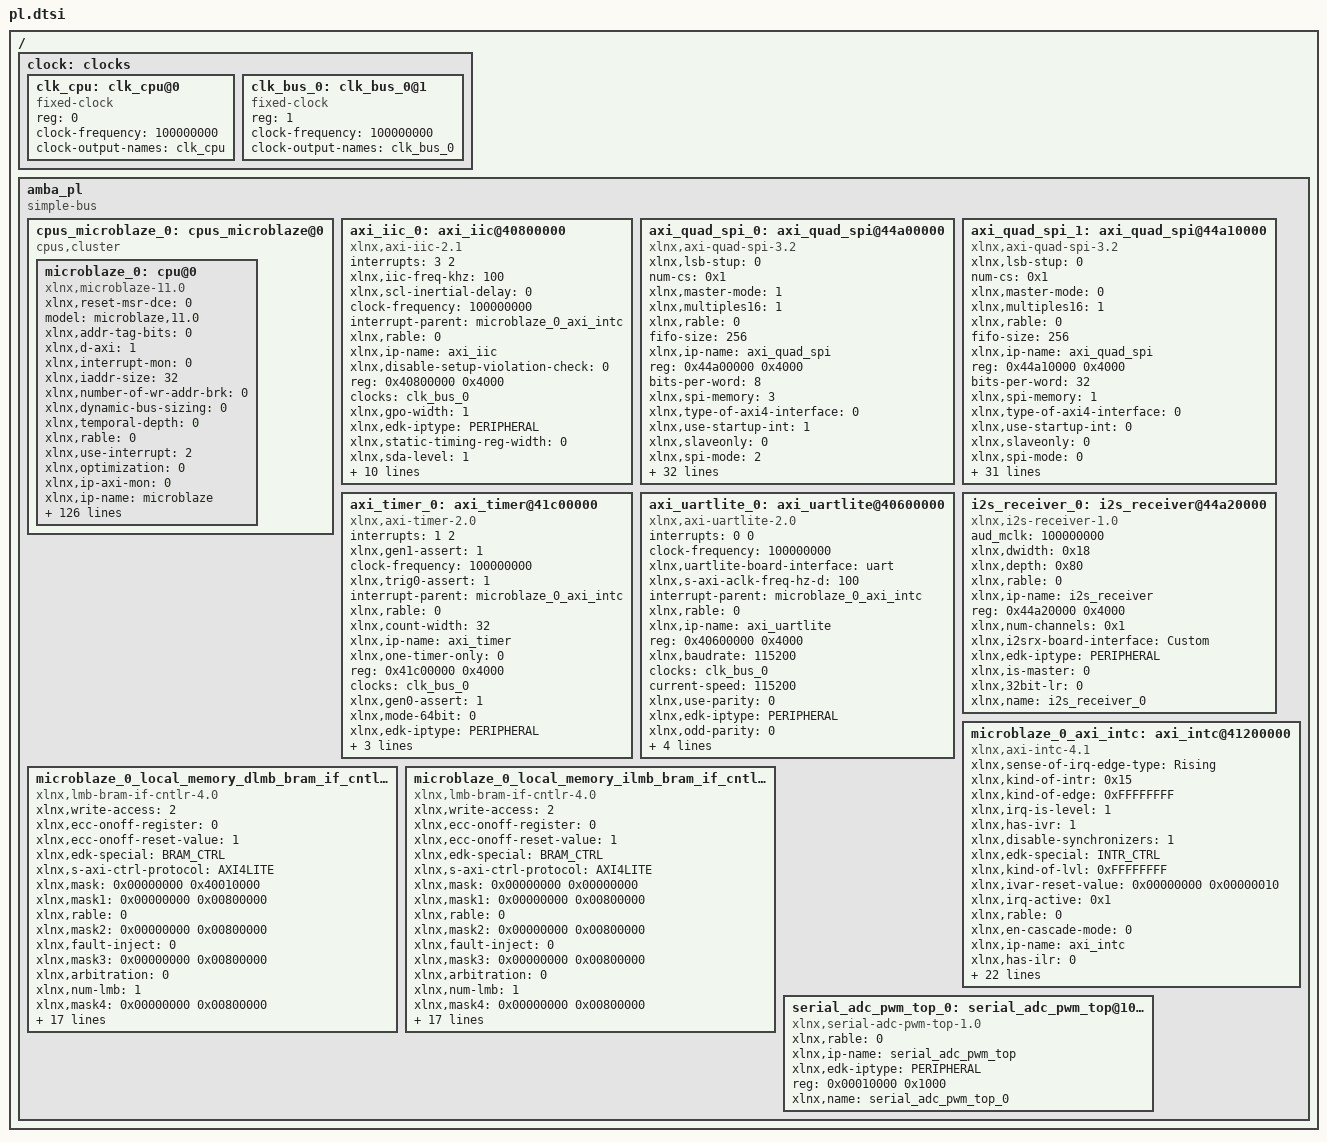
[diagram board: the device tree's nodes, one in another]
/ {
	clock: clocks {
		#address-cells = <1>;
		#size-cells = <0>;
		clk_cpu: clk_cpu@0 {
			compatible = "fixed-clock";
			reg = <0>;
			clock-frequency = <100000000>;
			clock-output-names = "clk_cpu";
			#clock-cells = <0>;
		};
		clk_bus_0: clk_bus_0@1 {
			compatible = "fixed-clock";
			reg = <1>;
			clock-frequency = <100000000>;
			clock-output-names = "clk_bus_0";
			#clock-cells = <0>;
		};
	};
	amba_pl: amba_pl {
		ranges;
		compatible = "simple-bus";
		#address-cells = <1>;
		#size-cells = <1>;
		cpus_microblaze_0: cpus_microblaze@0 {
			#cpu-mask-cells = <1>;
			compatible = "cpus,cluster";
			microblaze_0: cpu@0 {
				xlnx,reset-msr-dce = <0>;
				model = "microblaze,11.0";
				xlnx,addr-tag-bits = <0>;
				xlnx,d-axi = <1>;
				xlnx,interrupt-mon = <0>;
				xlnx,iaddr-size = <32>;
				xlnx,number-of-wr-addr-brk = <0>;
				xlnx,dynamic-bus-sizing = <0>;
				xlnx,temporal-depth = <0>;
				xlnx,rable = <0>;
				xlnx,use-interrupt = <2>;
				xlnx,optimization = <0>;
				xlnx,ip-axi-mon = <0>;
				xlnx,ip-name = "microblaze";
				d-cache-highaddr = <0x3fffffff>;
				xlnx,dcache-force-tag-lutram = <0>;
				xlnx,pc-width = <32>;
				xlnx,interrupt-is-edge = <0>;
				reg = <0x0>;
				xlnx,async-interrupt = <1>;
				xlnx,use-mmu = <0>;
				xlnx,reset-msr-ee = <0>;
				xlnx,icache-victims = <0>;
				xlnx,use-reorder-instr = <0>;
				xlnx,d-lmb-mon = <0>;
				xlnx,d-lmb-protocol = <0>;
				xlnx,ill-opcode-exception = <0>;
				xlnx,dcache-always-used = <1>;
				xlnx,use-div = <0>;
				xlnx,dc-axi-mon = <0>;
				xlnx,debug-trace-async-reset = <0>;
				xlnx,trace = <0>;
				xlnx,part = "xc7a100tcsg324-2";
				i-cache-baseaddr = <0x00000000>;
				xlnx,use-config-reset = <0>;
				xlnx,pvr = <0>;
				xlnx,i-lmb-mon = <0>;
				xlnx,dcache-byte-size = <4096>;
				xlnx,fault-tolerant = <0>;
				xlnx,family = "artix7";
				compatible = "xlnx,microblaze-11.0" , "xlnx,microblaze";
				xlnx,data-size = <32>;
				xlnx,mmu-zones = <2>;
				xlnx,debug-trace-size = <8192>;
				xlnx,mmu-privileged-instr = <0>;
				xlnx,enable-discrete-ports = <0>;
				d-cache-line-size = <16>;
				xlnx,d-lmb = <1>;
				xlnx,sco = <0>;
				xlnx,reset-msr-eip = <0>;
				clock-frequency = <100000000>;
				xlnx,debug-interface = <0>;
				xlnx,use-ext-brk = <0>;
				xlnx,daddr-size = <32>;
				xlnx,debug-enabled = <1>;
				xlnx,reset-msr-ice = <0>;
				xlnx,num-sync-ff-dbg-trace-clk = <2>;
				xlnx,i-lmb-protocol = <0>;
				xlnx,endianness = <1>;
				xlnx,fsl-exception = <0>;
				i-cache-line-size = <16>;
				xlnx,use-extended-fsl-instr = <0>;
				xlnx,reset-msr = <0x00000000>;
				xlnx,dp-axi-mon = <0>;
				xlnx,branch-target-cache-size = <0>;
				xlnx,dcache-use-writeback = <0>;
				xlnx,div-zero-exception = <0>;
				xlnx,mmu-tlb-access = <3>;
				bus-handle = <&amba_pl>;
				xlnx,cache-byte-size = <4096>;
				xlnx,pvr-user2 = <0x00000000>;
				xlnx,opcode-0x0-illegal = <0>;
				xlnx,icache-line-len = <4>;
				xlnx,ecc-use-ce-exception = <0>;
				xlnx,base-vectors = <0x00000000 0x00000000>;
				xlnx,use-dcache = <0>;
				xlnx,use-barrel = <1>;
				xlnx,reset-msr-bip = <0>;
				xlnx,edk-special = "microblaze";
				xlnx,allow-dcache-wr = <1>;
				xlnx,addr-size = <32>;
				xlnx,debug-external-trace = <0>;
				xlnx,piaddr-size = <32>;
				i-cache-highaddr = <0x3fffffff>;
				xlnx,num-sync-ff-clk-debug = <2>;
				xlnx,debug-event-counters = <5>;
				xlnx,fpu-exception = <0>;
				xlnx,allow-icache-wr = <1>;
				xlnx,i-axi = <0>;
				xlnx,g-use-exceptions = <0>;
				xlnx,icache-streams = <0>;
				xlnx,g-template-list = <8>;
				xlnx,dcache-line-len = <4>;
				xlnx,num-sync-ff-clk = <2>;
				xlnx,use-stack-protection = <0>;
				xlnx,use-hw-mul = <1>;
				xlnx,num-sync-ff-dbg-clk = <1>;
				xlnx,interconnect = <2>;
				xlnx,edk-iptype = "PROCESSOR";
				xlnx,debug-latency-counters = <1>;
				i-cache-size = <4096>;
				xlnx,use-fpu = <0>;
				xlnx,reset-msr-ie = <0>;
				xlnx,edge-is-positive = <1>;
				xlnx,use-pcmp-instr = <1>;
				xlnx,use-icache = <0>;
				d-cache-size = <4096>;
				xlnx,async-wakeup = <3>;
				xlnx,use-non-secure = <0>;
				xlnx,dcache-addr-tag = <0>;
				xlnx,number-of-rd-addr-brk = <0>;
				d-cache-baseaddr = <0x00000000>;
				xlnx,area-optimized = <1>;
				xlnx,avoid-primitives = <0>;
				xlnx,lockstep-slave = <0>;
				xlnx,use-ext-nm-brk = <0>;
				xlnx,instr-size = <32>;
				interrupt-handle = <&microblaze_0_axi_intc>;
				xlnx,icache-always-used = <1>;
				xlnx,i-lmb = <1>;
				xlnx,mmu-dtlb-size = <2>;
				xlnx,lockstep-select = <0>;
				xlnx,lmb-data-size = <32>;
				xlnx,ic-axi-mon = <0>;
				xlnx,num-sync-ff-clk-irq = <1>;
				xlnx,fsl-links = <0>;
				timebase-frequency = <100000000>;
				xlnx,icache-force-tag-lutram = <0>;
				xlnx,dcache-data-width = <0>;
				xlnx,dcache-victims = <0>;
				xlnx,use-branch-target-cache = <0>;
				xlnx,debug-profile-size = <0>;
				xlnx,unaligned-exceptions = <0>;
				xlnx,lockstep-master = <0>;
				xlnx,freq = <100000000>;
				xlnx,number-of-pc-brk = <1>;
				xlnx,mmu-itlb-size = <1>;
				xlnx,imprecise-exceptions = <0>;
				xlnx,use-msr-instr = <1>;
				xlnx,icache-data-width = <0>;
				xlnx,debug-counter-width = <32>;
			};
		};
		axi_iic_0: axi_iic@40800000 {
			interrupts = < 3 2 >;
			xlnx,iic-freq-khz = <100>;
			compatible = "xlnx,axi-iic-2.1" , "xlnx,xps-iic-2.00.a";
			xlnx,scl-inertial-delay = <0>;
			clock-frequency = <100000000>;
			interrupt-parent = <&microblaze_0_axi_intc>;
			xlnx,rable = <0>;
			xlnx,ip-name = "axi_iic";
			xlnx,disable-setup-violation-check = <0>;
			reg = <0x40800000 0x4000>;
			clocks = <&clk_bus_0>;
			xlnx,gpo-width = <1>;
			xlnx,edk-iptype = "PERIPHERAL";
			xlnx,static-timing-reg-width = <0>;
			xlnx,sda-level = <1>;
			status = "okay";
			xlnx,use-board-flow;
			xlnx,ten-bit-adr = <0>;
			xlnx,default-value = <0x00>;
			interrupt-names = "iic2intc_irpt";
			xlnx,timing-reg-width = <32>;
			xlnx,iic-board-interface = "iic_main";
			xlnx,iic-freq = <100000>;
			xlnx,smbus-pmbus-host = <0>;
			xlnx,sda-inertial-delay = <0>;
			xlnx,name = "axi_iic_0";
			xlnx,axi-aclk-freq-mhz = <100>;
		};
		axi_quad_spi_0: axi_quad_spi@44a00000 {
			xlnx,lsb-stup = <0>;
			num-cs = <0x1>;
			xlnx,master-mode = <1>;
			xlnx,multiples16 = <1>;
			xlnx,rable = <0>;
			fifo-size = <256>;
			xlnx,ip-name = "axi_quad_spi";
			reg = <0x44a00000 0x4000>;
			bits-per-word = <8>;
			xlnx,spi-memory = <3>;
			xlnx,type-of-axi4-interface = <0>;
			xlnx,use-startup-int = <1>;
			xlnx,slaveonly = <0>;
			xlnx,spi-mode = <2>;
			interrupt-names = "ip2intc_irpt";
			compatible = "xlnx,axi-quad-spi-3.2" , "xlnx,xps-spi-2.00.a";
			xlnx,byte-level-interrupt-en = <0>;
			xlnx,s-axi4-addr-width = <24>;
			xlnx,sck-ratio = <2>;
			interrupt-parent = <&microblaze_0_axi_intc>;
			xlnx,startup-block;
			xlnx,async-clk = <0>;
			status = "okay";
			xlnx,sck-ratio1 = <1>;
			xlnx,use-board-flow;
			xlnx,fifo-included = <1>;
			xlnx,name = "axi_quad_spi_0";
			interrupts = < 2 0 >;
			xlnx,use-startup-ext = <0>;
			xlnx,hasfifos = <1>;
			xlnx,s-axi4-id-width = <4>;
			xlnx,shared-startup = <0>;
			xlnx,new-seq-en = <1>;
			xlnx,qspi-board-interface = "spi_flash";
			xlnx,edk-iptype = "PERIPHERAL";
			xlnx,fifo-depth = <256>;
			xlnx,axi-interface = <0>;
			xlnx,num-ss-bits = <0x1>;
			xlnx,select-xpm = <0>;
			xlnx,xip-mode = <0>;
			xlnx,xip-perf-mode = <1>;
			xlnx,dual-quad-mode = <0>;
			xlnx,num-transfer-bits = <8>;
			xlnx,s-axi4-data-width = <32>;
			xlnx,use-startup = <1>;
			xlnx,spi-mem-addr-bits = <24>;
			xlnx,uc-family = <0>;
			xlnx,Axi4-address = <0>;
			xlnx,sub-family = "artix7";
		};
		axi_quad_spi_1: axi_quad_spi@44a10000 {
			xlnx,lsb-stup = <0>;
			num-cs = <0x1>;
			xlnx,master-mode = <0>;
			xlnx,multiples16 = <1>;
			xlnx,rable = <0>;
			fifo-size = <256>;
			xlnx,ip-name = "axi_quad_spi";
			reg = <0x44a10000 0x4000>;
			bits-per-word = <32>;
			xlnx,spi-memory = <1>;
			xlnx,type-of-axi4-interface = <0>;
			xlnx,use-startup-int = <0>;
			xlnx,slaveonly = <0>;
			xlnx,spi-mode = <0>;
			interrupt-names = "ip2intc_irpt";
			compatible = "xlnx,axi-quad-spi-3.2" , "xlnx,xps-spi-2.00.a";
			xlnx,byte-level-interrupt-en = <0>;
			xlnx,s-axi4-addr-width = <24>;
			xlnx,sck-ratio = <8>;
			interrupt-parent = <&microblaze_0_axi_intc>;
			xlnx,async-clk = <0>;
			status = "okay";
			xlnx,sck-ratio1 = <1>;
			xlnx,use-board-flow;
			xlnx,fifo-included = <1>;
			xlnx,name = "axi_quad_spi_1";
			interrupts = < 4 0 >;
			xlnx,use-startup-ext = <0>;
			xlnx,hasfifos = <1>;
			xlnx,s-axi4-id-width = <4>;
			xlnx,shared-startup = <0>;
			xlnx,new-seq-en = <1>;
			xlnx,qspi-board-interface = "Custom";
			xlnx,edk-iptype = "PERIPHERAL";
			xlnx,fifo-depth = <256>;
			xlnx,axi-interface = <0>;
			xlnx,num-ss-bits = <0x1>;
			xlnx,select-xpm = <0>;
			xlnx,xip-mode = <0>;
			xlnx,xip-perf-mode = <1>;
			xlnx,dual-quad-mode = <0>;
			xlnx,num-transfer-bits = <32>;
			xlnx,s-axi4-data-width = <32>;
			xlnx,use-startup = <0>;
			xlnx,spi-mem-addr-bits = <24>;
			xlnx,uc-family = <0>;
			xlnx,sub-family = "artix7";
			xlnx,Axi4-address = <0>;
		};
		axi_timer_0: axi_timer@41c00000 {
			interrupts = < 1 2 >;
			compatible = "xlnx,axi-timer-2.0" , "xlnx,xps-timer-1.00.a";
			xlnx,gen1-assert = <1>;
			clock-frequency = <100000000>;
			xlnx,trig0-assert = <1>;
			interrupt-parent = <&microblaze_0_axi_intc>;
			xlnx,rable = <0>;
			xlnx,count-width = <32>;
			xlnx,ip-name = "axi_timer";
			xlnx,one-timer-only = <0>;
			reg = <0x41c00000 0x4000>;
			clocks = <&clk_bus_0>;
			xlnx,gen0-assert = <1>;
			xlnx,mode-64bit = <0>;
			xlnx,edk-iptype = "PERIPHERAL";
			xlnx,trig1-assert = <1>;
			status = "okay";
			xlnx,enable-timer2 = <1>;
			interrupt-names = "interrupt";
			xlnx,name = "axi_timer_0";
		};
		axi_uartlite_0: axi_uartlite@40600000 {
			interrupts = < 0 0 >;
			compatible = "xlnx,axi-uartlite-2.0" , "xlnx,xps-uartlite-1.00.a";
			clock-frequency = <100000000>;
			xlnx,uartlite-board-interface = "uart";
			xlnx,s-axi-aclk-freq-hz-d = <100>;
			interrupt-parent = <&microblaze_0_axi_intc>;
			xlnx,rable = <0>;
			xlnx,ip-name = "axi_uartlite";
			reg = <0x40600000 0x4000>;
			xlnx,baudrate = <115200>;
			clocks = <&clk_bus_0>;
			current-speed = <115200>;
			xlnx,use-parity = <0>;
			xlnx,edk-iptype = "PERIPHERAL";
			xlnx,odd-parity = <0>;
			status = "okay";
			xlnx,use-board-flow;
			interrupt-names = "interrupt";
			xlnx,name = "axi_uartlite_0";
			xlnx,data-bits = <8>;
			xlnx,parity = "No_Parity";
		};
		i2s_receiver_0: i2s_receiver@44a20000 {
			aud_mclk = <100000000>;
			compatible = "xlnx,i2s-receiver-1.0" , "xlnx,i2s-receiver-1.0";
			xlnx,dwidth = <0x18>;
			xlnx,depth = <0x80>;
			xlnx,rable = <0>;
			xlnx,ip-name = "i2s_receiver";
			reg = <0x44a20000 0x4000>;
			xlnx,num-channels = <0x1>;
			xlnx,i2srx-board-interface = "Custom";
			xlnx,edk-iptype = "PERIPHERAL";
			xlnx,is-master = <0>;
			status = "okay";
			xlnx,32bit-lr = <0>;
			xlnx,name = "i2s_receiver_0";
		};
		microblaze_0_axi_intc: axi_intc@41200000 {
			#interrupt-cells = <2>;
			xlnx,sense-of-irq-edge-type = "Rising";
			xlnx,kind-of-intr = <0x15>;
			xlnx,kind-of-edge = <0xFFFFFFFF>;
			xlnx,irq-is-level = <1>;
			xlnx,has-ivr = <1>;
			compatible = "xlnx,axi-intc-4.1" , "xlnx,xps-intc-1.00.a";
			xlnx,disable-synchronizers = <1>;
			xlnx,edk-special = "INTR_CTRL";
			xlnx,kind-of-lvl = <0xFFFFFFFF>;
			xlnx,ivar-reset-value = <0x00000000 0x00000010>;
			xlnx,irq-active = <0x1>;
			xlnx,rable = <0>;
			xlnx,en-cascade-mode = <0>;
			xlnx,ip-name = "axi_intc";
			xlnx,has-ilr = <0>;
			reg = <0x41200000 0x4000>;
			xlnx,addr-width = <0x20>;
			xlnx,s-axi-aclk-freq-mhz = <100>;
			xlnx,num-sw-intr = <2>;
			xlnx,irq-connection = <0>;
			xlnx,num-intr-inputs = <0x6>;
			xlnx,has-sie = <1>;
			xlnx,has-cie = <1>;
			xlnx,enable-async = <0>;
			xlnx,num-sync-ff = <2>;
			xlnx,mb-clk-not-connected = <1>;
			xlnx,has-ipr = <1>;
			xlnx,edk-iptype = "PERIPHERAL";
			xlnx,sense-of-irq-level-type = "Active_High";
			xlnx,cascade-master = <0>;
			xlnx,processor-clk-freq-mhz = <100>;
			status = "okay";
			xlnx,is-fast = <0x1>;
			xlnx,has-fast = <1>;
			xlnx,ivar-rst-val = <0x0000000000000010>;
			interrupt-controller;
			xlnx,async-intr = <0xFFFFFFE0>;
			xlnx,name = "microblaze_0_axi_intc";
		};
		microblaze_0_local_memory_dlmb_bram_if_cntlr: lmb_bram_if_cntlr@0 {
			xlnx,write-access = <2>;
			compatible = "xlnx,lmb-bram-if-cntlr-4.0";
			xlnx,ecc-onoff-register = <0>;
			xlnx,ecc-onoff-reset-value = <1>;
			xlnx,edk-special = "BRAM_CTRL";
			xlnx,s-axi-ctrl-protocol = "AXI4LITE";
			xlnx,mask = <0x00000000 0x40010000>;
			xlnx,mask1 = <0x00000000 0x00800000>;
			xlnx,rable = <0>;
			xlnx,mask2 = <0x00000000 0x00800000>;
			xlnx,fault-inject = <0>;
			xlnx,mask3 = <0x00000000 0x00800000>;
			xlnx,arbitration = <0>;
			xlnx,num-lmb = <1>;
			xlnx,mask4 = <0x00000000 0x00800000>;
			reg = <0x00000000 0x8000>;
			xlnx,s-axi-ctrl-addr-width = <32>;
			xlnx,mask5 = <0x00000000 0x00800000>;
			xlnx,ecc-status-registers = <0>;
			xlnx,mask6 = <0x00000000 0x00800000>;
			xlnx,lmb-protocol = <0>;
			xlnx,ce-counter-width = <0>;
			xlnx,mask7 = <0x00000000 0x00800000>;
			xlnx,ecc = <0>;
			xlnx,lmb-dwidth = <32>;
			xlnx,interconnect = <0>;
			xlnx,ce-failing-registers = <0>;
			xlnx,edk-iptype = "PERIPHERAL";
			xlnx,ue-failing-registers = <0>;
			xlnx,s-axi-ctrl-data-width = <32>;
			xlnx,bram-awidth = <32>;
			xlnx,lmb-awidth = <32>;
		};
		microblaze_0_local_memory_ilmb_bram_if_cntlr: lmb_bram_if_cntlr@1 {
			xlnx,write-access = <2>;
			compatible = "xlnx,lmb-bram-if-cntlr-4.0";
			xlnx,ecc-onoff-register = <0>;
			xlnx,ecc-onoff-reset-value = <1>;
			xlnx,edk-special = "BRAM_CTRL";
			xlnx,s-axi-ctrl-protocol = "AXI4LITE";
			xlnx,mask = <0x00000000 0x00000000>;
			xlnx,mask1 = <0x00000000 0x00800000>;
			xlnx,rable = <0>;
			xlnx,mask2 = <0x00000000 0x00800000>;
			xlnx,fault-inject = <0>;
			xlnx,mask3 = <0x00000000 0x00800000>;
			xlnx,arbitration = <0>;
			xlnx,num-lmb = <1>;
			xlnx,mask4 = <0x00000000 0x00800000>;
			reg = <0x00000000 0x8000>;
			xlnx,s-axi-ctrl-addr-width = <32>;
			xlnx,mask5 = <0x00000000 0x00800000>;
			xlnx,ecc-status-registers = <0>;
			xlnx,mask6 = <0x00000000 0x00800000>;
			xlnx,lmb-protocol = <0>;
			xlnx,ce-counter-width = <0>;
			xlnx,mask7 = <0x00000000 0x00800000>;
			xlnx,ecc = <0>;
			xlnx,lmb-dwidth = <32>;
			xlnx,interconnect = <0>;
			xlnx,ce-failing-registers = <0>;
			xlnx,edk-iptype = "PERIPHERAL";
			xlnx,ue-failing-registers = <0>;
			xlnx,s-axi-ctrl-data-width = <32>;
			xlnx,bram-awidth = <32>;
			xlnx,lmb-awidth = <32>;
		};
		serial_adc_pwm_top_0: serial_adc_pwm_top@10000 {
			xlnx,rable = <0>;
			compatible = "xlnx,serial-adc-pwm-top-1.0";
			status = "okay";
			xlnx,ip-name = "serial_adc_pwm_top";
			xlnx,edk-iptype = "PERIPHERAL";
			reg = <0x00010000 0x1000>;
			xlnx,name = "serial_adc_pwm_top_0";
		};
	};
};
